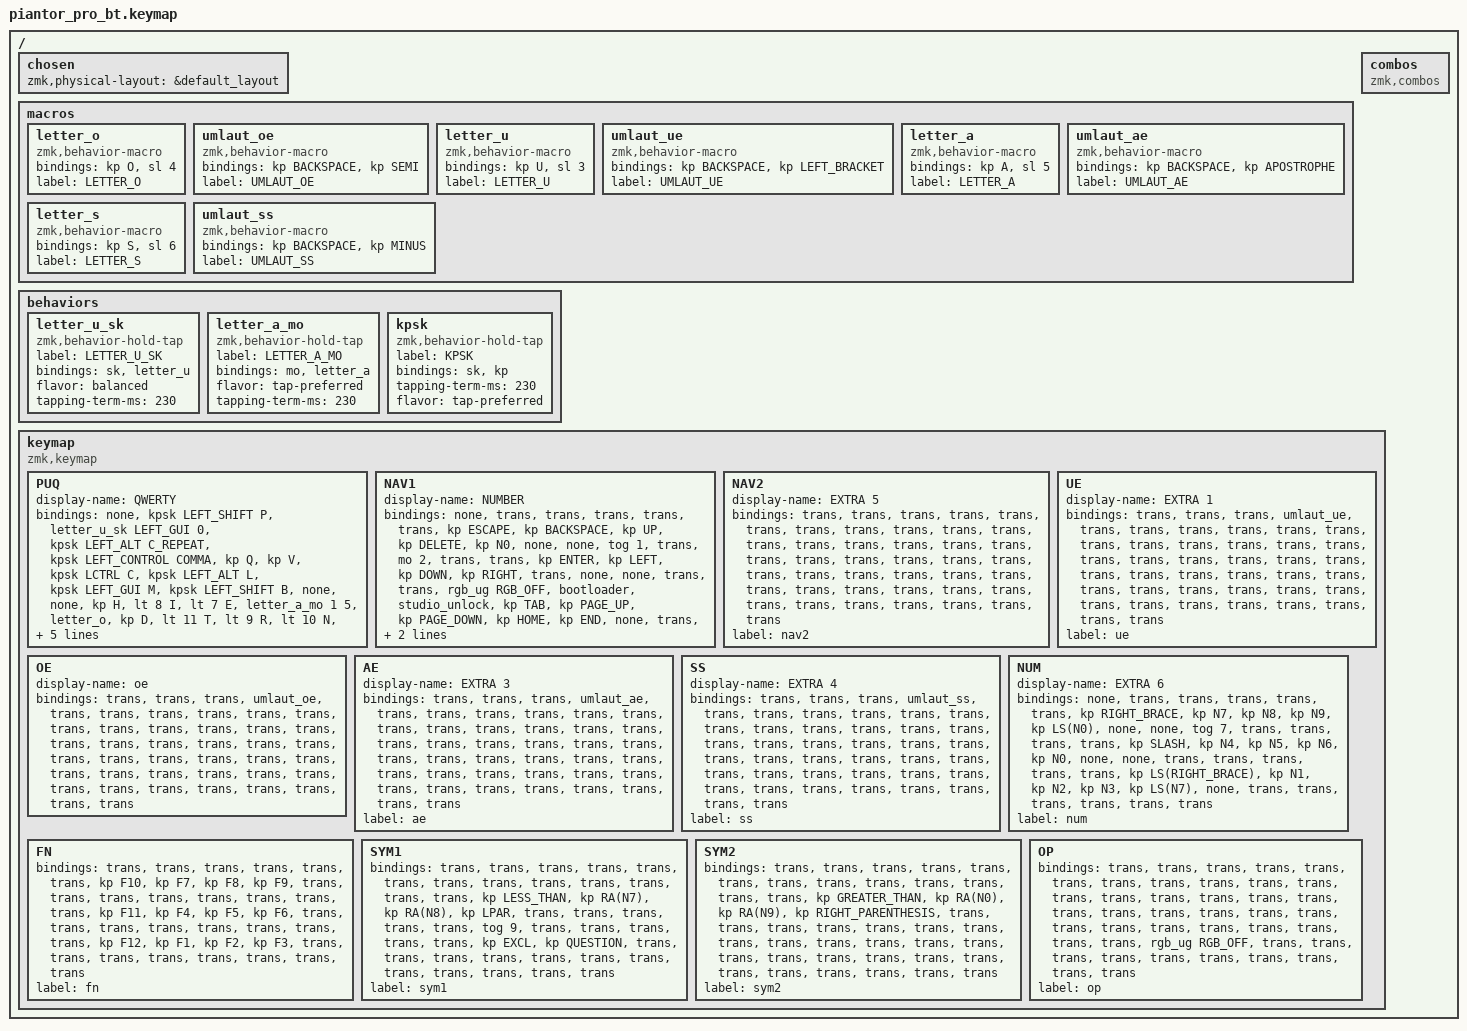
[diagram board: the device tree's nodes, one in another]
/*
 * Copyright (c) 2020 The ZMK Contributors
 *
 * SPDX-License-Identifier: MIT
 */

#include <behaviors.dtsi>
#include <dt-bindings/zmk/keys.h>
#include <dt-bindings/zmk/rgb.h>

/ {
    chosen { zmk,physical-layout = &default_layout; };
};

/ {
    macros {
        letter_o: letter_o {
            compatible = "zmk,behavior-macro";
            #binding-cells = <0>;
            bindings = <&kp O &sl 4>;
            label = "LETTER_O";
        };

        umlaut_oe: umlaut_oe {
            compatible = "zmk,behavior-macro";
            #binding-cells = <0>;
            bindings = <&kp BACKSPACE &kp SEMI>;
            label = "UMLAUT_OE";
        };

        letter_u: letter_u {
            compatible = "zmk,behavior-macro";
            #binding-cells = <0>;
            bindings = <&kp U &sl 3>;
            label = "LETTER_U";
        };

        umlaut_ue: umlaut_ue {
            compatible = "zmk,behavior-macro";
            #binding-cells = <0>;
            bindings = <&kp BACKSPACE &kp LEFT_BRACKET>;
            label = "UMLAUT_UE";
        };

        letter_a: letter_a {
            compatible = "zmk,behavior-macro";
            #binding-cells = <0>;
            bindings = <&kp A &sl 5>;
            label = "LETTER_A";
        };

        umlaut_ae: umlaut_ae {
            compatible = "zmk,behavior-macro";
            #binding-cells = <0>;
            bindings = <&kp BACKSPACE &kp APOSTROPHE>;
            label = "UMLAUT_AE";
        };

        letter_s: letter_s {
            compatible = "zmk,behavior-macro";
            #binding-cells = <0>;
            bindings = <&kp S &sl 6>;
            label = "LETTER_S";
        };

        umlaut_ss: umlaut_ss {
            compatible = "zmk,behavior-macro";
            #binding-cells = <0>;
            bindings = <&kp BACKSPACE &kp MINUS>;
            label = "UMLAUT_SS";
        };
    };

    behaviors {
        letter_u_sk: letter_u_sk {
            compatible = "zmk,behavior-hold-tap";
            label = "LETTER_U_SK";
            bindings = <&sk>, <&letter_u>;

            #binding-cells = <2>;
            flavor = "balanced";
            tapping-term-ms = <230>;
        };

        letter_a_mo: letter_a_mo {
            compatible = "zmk,behavior-hold-tap";
            label = "LETTER_A_MO";
            bindings = <&mo>, <&letter_a>;

            #binding-cells = <2>;
            flavor = "tap-preferred";
            tapping-term-ms = <230>;
        };

        kpsk: kpsk {
            compatible = "zmk,behavior-hold-tap";
            label = "KPSK";
            bindings = <&sk>, <&kp>;

            #binding-cells = <2>;
            tapping-term-ms = <230>;
            flavor = "tap-preferred";
        };
    };

    combos { compatible = "zmk,combos"; };

    keymap {
        compatible = "zmk,keymap";

        PUQ {
            display-name = "QWERTY";

            // --------------------------------------------------------------------------------
            // |  TAB |  Q  |  W  |  E  |  R  |  T  |  Y  |  U   |  I  |  O  |  P  | BSPC |
            // | CTRL |  A  |  S  |  D  |  F  |  G  |  H  |  J   |  K  |  L  |  ;  |  '   |
            // | SHFT |  Z  |  X  |  C  |  V  |  B  |  N  |  M   |  ,  |  .  |  /  | ESC  |
            //                    | GUI | LWR | SPC | ENT | RSE  | ALT |

            bindings = <
&none  &kpsk LEFT_SHIFT P  &letter_u_sk LEFT_GUI 0  &kpsk LEFT_ALT C_REPEAT  &kpsk LEFT_CONTROL COMMA  &kp Q  &kp V  &kpsk LCTRL C  &kpsk LEFT_ALT L  &kpsk LEFT_GUI M  &kpsk LEFT_SHIFT B  &none  &none  &kp H  &lt 8 I  &lt 7 E  &letter_a_mo 1 5  &letter_o  &kp D  &lt 11 T  &lt 9 R  &lt 10 N  &letter_s  &none  &none  &kp K  &kp Z  &kp DOT  &kp LS(BACKSLASH)  &kp X  &kp J  &kp G  &kp Y  &kp W  &kp F  &none  &sk LSHFT  &kp SPACE  &sk LCTRL  &sk LCTRL  &kp SPACE  &sk LSHFT
            >;

            label = "puq";
        };

        NAV1 {
            display-name = "NUMBER";

            // -----------------------------------------------------------------------------------------
            // |  TAB |  1  |  2  |  3  |  4  |  5    |  6  |  7  |  8  |  9  |  0  | BSPC |
            // | CTRL | BT1 | BT2 | BT3 | BT4 | BT5   | LFT | DWN |  UP | RGT |     |      |
            // | SHFT | BTCR| RGB | RST | BOOT| Unlock|     |     |     |     |     |      |
            //                    | GUI |     | SPC   | ENT |     | ALT |

            bindings = <
&none  &trans  &trans  &trans  &trans  &trans  &kp ESCAPE  &kp BACKSPACE  &kp UP  &kp DELETE  &kp N0  &none  &none  &tog 1  &trans  &mo 2  &trans  &trans  &kp ENTER  &kp LEFT  &kp DOWN  &kp RIGHT  &trans  &none  &none  &trans  &trans  &rgb_ug RGB_OFF  &bootloader  &studio_unlock  &kp TAB  &kp PAGE_UP  &kp PAGE_DOWN  &kp HOME  &kp END  &none  &trans  &trans  &trans  &trans  &trans  &trans
            >;

            label = "nav1";
        };

        NAV2 {
            display-name = "EXTRA 5";
            bindings = <
&trans  &trans  &trans  &trans  &trans  &trans  &trans  &trans  &trans  &trans  &trans  &trans  &trans  &trans  &trans  &trans  &trans  &trans  &trans  &trans  &trans  &trans  &trans  &trans  &trans  &trans  &trans  &trans  &trans  &trans  &trans  &trans  &trans  &trans  &trans  &trans  &trans  &trans  &trans  &trans  &trans  &trans
            >;

            label = "nav2";
        };

        UE {
            display-name = "EXTRA 1";
            bindings = <
&trans  &trans  &trans  &umlaut_ue  &trans  &trans  &trans  &trans  &trans  &trans  &trans  &trans  &trans  &trans  &trans  &trans  &trans  &trans  &trans  &trans  &trans  &trans  &trans  &trans  &trans  &trans  &trans  &trans  &trans  &trans  &trans  &trans  &trans  &trans  &trans  &trans  &trans  &trans  &trans  &trans  &trans  &trans
            >;

            label = "ue";
        };

        OE {
            display-name = "oe";
            bindings = <
&trans  &trans  &trans  &umlaut_oe  &trans  &trans  &trans  &trans  &trans  &trans  &trans  &trans  &trans  &trans  &trans  &trans  &trans  &trans  &trans  &trans  &trans  &trans  &trans  &trans  &trans  &trans  &trans  &trans  &trans  &trans  &trans  &trans  &trans  &trans  &trans  &trans  &trans  &trans  &trans  &trans  &trans  &trans
            >;
        };

        AE {
            display-name = "EXTRA 3";
            bindings = <
&trans  &trans  &trans  &umlaut_ae  &trans  &trans  &trans  &trans  &trans  &trans  &trans  &trans  &trans  &trans  &trans  &trans  &trans  &trans  &trans  &trans  &trans  &trans  &trans  &trans  &trans  &trans  &trans  &trans  &trans  &trans  &trans  &trans  &trans  &trans  &trans  &trans  &trans  &trans  &trans  &trans  &trans  &trans
            >;

            label = "ae";
        };

        SS {
            display-name = "EXTRA 4";
            bindings = <
&trans  &trans  &trans  &umlaut_ss  &trans  &trans  &trans  &trans  &trans  &trans  &trans  &trans  &trans  &trans  &trans  &trans  &trans  &trans  &trans  &trans  &trans  &trans  &trans  &trans  &trans  &trans  &trans  &trans  &trans  &trans  &trans  &trans  &trans  &trans  &trans  &trans  &trans  &trans  &trans  &trans  &trans  &trans
            >;

            label = "ss";
        };

        NUM {
            display-name = "EXTRA 6";
            bindings = <
&none  &trans  &trans  &trans  &trans  &trans  &kp RIGHT_BRACE  &kp N7  &kp N8  &kp N9  &kp LS(N0)  &none  &none  &tog 7  &trans  &trans  &trans  &trans  &kp SLASH  &kp N4  &kp N5  &kp N6  &kp N0  &none  &none  &trans  &trans  &trans  &trans  &trans  &kp LS(RIGHT_BRACE)  &kp N1  &kp N2  &kp N3  &kp LS(N7)  &none  &trans  &trans  &trans  &trans  &trans  &trans
            >;

            label = "num";
        };

        FN {
            bindings = <
&trans  &trans  &trans  &trans  &trans  &trans  &kp F10  &kp F7  &kp F8  &kp F9  &trans  &trans  &trans  &trans  &trans  &trans  &trans  &trans  &kp F11  &kp F4  &kp F5  &kp F6  &trans  &trans  &trans  &trans  &trans  &trans  &trans  &trans  &kp F12  &kp F1  &kp F2  &kp F3  &trans  &trans  &trans  &trans  &trans  &trans  &trans  &trans
            >;

            label = "fn";
        };

        SYM1 {
            bindings = <
&trans  &trans  &trans  &trans  &trans  &trans  &trans  &trans  &trans  &trans  &trans  &trans  &trans  &kp LESS_THAN  &kp RA(N7)  &kp RA(N8)  &kp LPAR  &trans  &trans  &trans  &trans  &trans  &tog 9  &trans  &trans  &trans  &trans  &trans  &kp EXCL  &kp QUESTION  &trans  &trans  &trans  &trans  &trans  &trans  &trans  &trans  &trans  &trans  &trans  &trans
            >;

            label = "sym1";
        };

        SYM2 {
            bindings = <
&trans  &trans  &trans  &trans  &trans  &trans  &trans  &trans  &trans  &trans  &trans  &trans  &trans  &kp GREATER_THAN  &kp RA(N0)  &kp RA(N9)  &kp RIGHT_PARENTHESIS  &trans  &trans  &trans  &trans  &trans  &trans  &trans  &trans  &trans  &trans  &trans  &trans  &trans  &trans  &trans  &trans  &trans  &trans  &trans  &trans  &trans  &trans  &trans  &trans  &trans
            >;

            label = "sym2";
        };

        OP {
            bindings = <
&trans  &trans  &trans  &trans  &trans  &trans  &trans  &trans  &trans  &trans  &trans  &trans  &trans  &trans  &trans  &trans  &trans  &trans  &trans  &trans  &trans  &trans  &trans  &trans  &trans  &trans  &trans  &trans  &trans  &trans  &trans  &rgb_ug RGB_OFF  &trans  &trans  &trans  &trans  &trans  &trans  &trans  &trans  &trans  &trans
            >;

            label = "op";
        };
    };
};
